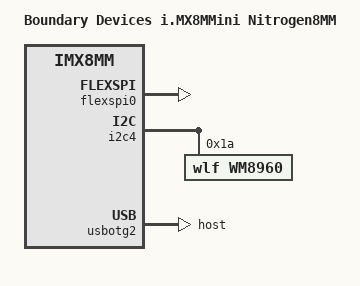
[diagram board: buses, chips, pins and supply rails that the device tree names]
/*
 * Copyright 2018 NXP
 *
 * This program is free software; you can redistribute it and/or
 * modify it under the terms of the GNU General Public License
 * as published by the Free Software Foundation; either version 2
 * of the License, or (at your option) any later version.
 *
 * This program is distributed in the hope that it will be useful,
 * but WITHOUT ANY WARRANTY; without even the implied warranty of
 * MERCHANTABILITY or FITNESS FOR A PARTICULAR PURPOSE.  See the
 * GNU General Public License for more details.
 */
/dts-v1/;
#define MX8MMN(a, b)	MX8MM_##a b
#define IMX8MMN(a)	IMX8MM_##a
#include "fsl-imx8mm.dtsi"

&iomuxc {
	pinctrl_sai1: sai1grp {
		fsl,pins = <
			/* wm8960 */
			MX8MMN(IOMUXC_SAI1_MCLK_SAI1_MCLK, 0xd6)
			MX8MMN(IOMUXC_SAI1_TXFS_SAI1_TX_SYNC, 0xd6)
			MX8MMN(IOMUXC_SAI1_TXC_SAI1_TX_BCLK, 0xd6)
			MX8MMN(IOMUXC_SAI1_TXD0_SAI1_TX_DATA0, 0xd6)
			MX8MMN(IOMUXC_SAI1_RXD0_SAI1_RX_DATA0, 0xd6)
		>;
	};

	pinctrl_usbotg2: usbotg2grp {
		fsl,pins = <
			MX8MMN(IOMUXC_GPIO1_IO14_USB2_OTG_PWR, 0x16)
			MX8MMN(IOMUXC_GPIO1_IO15_USB2_OTG_OC, 0x16)
		>;
	};

	pinctrl_flexspi: flexspigrp {
		fsl,pins = <
			MX8MMN(IOMUXC_NAND_ALE_QSPI_A_SCLK, 0x1c2)
			MX8MMN(IOMUXC_NAND_CE0_B_QSPI_A_SS0_B, 0x82)
			MX8MMN(IOMUXC_NAND_DATA00_QSPI_A_DATA0, 0x82)
			MX8MMN(IOMUXC_NAND_DATA01_QSPI_A_DATA1, 0x82)
			MX8MMN(IOMUXC_NAND_DATA02_QSPI_A_DATA2, 0x82)
			MX8MMN(IOMUXC_NAND_DATA03_QSPI_A_DATA3, 0x82)
		>;
	};

};

#include "imx8mmn-nitrogen8mm.dtsi"

/ {
	model = "Boundary Devices i.MX8MMini Nitrogen8MM";
	compatible = "boundary,imx8mm-nitrogen8mm", "fsl,imx8mm";
};

&flexspi0 {
	pinctrl-names = "default";
	pinctrl-0 = <&pinctrl_flexspi>;
	status = "okay";
};

&i2c4 {
	wm8960: codec@1a {
		compatible = "wlf,wm8960";
		reg = <0x1a>;
		clocks = <&clk IMX8MMN(CLK_SAI1_ROOT)>;
		clock-names = "mclk";
		wlf,shared-lrclk;
	};
};

&usbotg2 {
	pinctrl-names = "default";
	pinctrl-0 = <&pinctrl_usbotg2>;
	power-polarity-active-high;
	dr_mode = "host";
	status = "okay";
};
